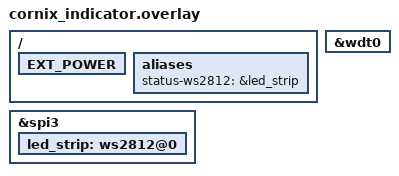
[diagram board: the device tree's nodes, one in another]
&spi3 {
    status = "okay";

    led_strip: ws2812@0 {
        status = "okay";
    };
};

/ {
    EXT_POWER {
        status = "okay";
    };

    aliases {
        status-ws2812 = &led_strip;
    };
};

/* Watchdog for issue #14 auto-recovery (driven by src/wdt_recovery.c). */
&wdt0 {
    status = "okay";
};

//vim: set ft=dts:
